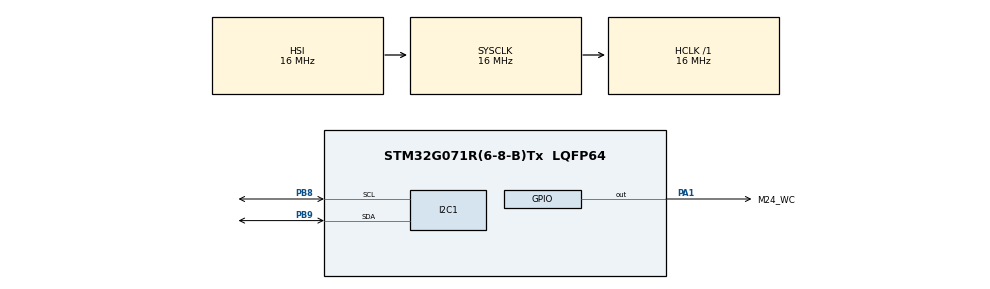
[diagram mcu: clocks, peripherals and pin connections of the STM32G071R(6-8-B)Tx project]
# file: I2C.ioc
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I2C1.Timing=0x00503D58
Mcu.Family=STM32G0
Mcu.Name=STM32G071R(6-8-B)Tx
Mcu.Package=LQFP64
PA1.GPIO_Label=M24_WC
PA1.Signal=GPIO_Output
PA13.Mode=Serial_Wire
PA13.Signal=SYS_SWDIO
PA14-BOOT0.Mode=Serial_Wire
PA14-BOOT0.Signal=SYS_SWCLK
PB8.Mode=I2C
PB8.Signal=I2C1_SCL
PB9.Mode=I2C
PB9.Signal=I2C1_SDA
ProjectManager.HeapSize=0x200
ProjectManager.StackSize=0x400
ProjectManager.TargetToolchain=STM32CubeIDE
RCC.AHBFreq_Value=16000000
RCC.CortexFreq_Value=16000000
RCC.EXTERNAL_CLOCK_VALUE=48000
RCC.HCLKFreq_Value=16000000
RCC.HSE_VALUE=8000000
RCC.HSI_VALUE=16000000
RCC.LSE_VALUE=32768
RCC.SYSCLKFreq_VALUE=16000000
RCC.VCOOutputFreq_Value=128000000
board=custom

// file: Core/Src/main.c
/* USER CODE BEGIN Header */
/**
  ******************************************************************************
  * @file           : main.c
  * @brief          : Main program body
  ******************************************************************************
  * @attention
  *
  * Copyright (c) 2024 STMicroelectronics.
  * All rights reserved.
  *
  * This software is licensed under terms that can be found in the LICENSE file
  * in the root directory of this software component.
  * If no LICENSE file comes with this software, it is provided AS-IS.
  *
  ******************************************************************************
  */
/* USER CODE END Header */
#include "main.h"
#include "i2c.h"
#include "gpio.h"
#include "M24.h"

void SystemClock_Config(void);

int main(void)
{

  /* USER CODE BEGIN 1 */

	uint8_t ReadValue =0;
	uint8_t M24Type;
	uint8_t TxData1 ='A';
	uint8_t TxData2 ='B';
	uint8_t TxData3 ='C';

  /* USER CODE END 1 */

  /* MCU Configuration--------------------------------------------------------*/

  /* Reset of all peripherals, Initializes the Flash interface and the Systick. */
  HAL_Init();

  /* Configure the system clock */
  SystemClock_Config();

  /* Initialize all configured peripherals */
  MX_GPIO_Init();
  MX_I2C1_Init();
  /* USER CODE BEGIN 2 */
  HAL_GPIO_WritePin(M24_WC_GPIO_Port,M24_WC_Pin, GPIO_PIN_RESET);

  /* USER CODE END 2 */

  /* Infinite loop */
  /* USER CODE BEGIN WHILE */
  while (1)
  {

	  M24Type =M24C02_I2C_ADDR;
	  WriteByteM24(M24Type,0x00000001,TxData1);
	  ReadValue =0;
	  ReadValue = ReadByteM24(M24Type,0x00000001);
	  if(TxData1 ==ReadValue) {
		  HAL_Delay(1);
	  }
	  M24Type =M24256_I2C_ADDR;
	  WriteByteM24(M24Type, 0x00000001,TxData2);
	  ReadValue =0;
	  ReadValue = ReadByteM24(M24Type,0x00000001);
	  if(TxData2 ==ReadValue) {
		  HAL_Delay(1);
	  }
	  M24Type =M24M01_I2C_ADDR;
	  WriteByteM24(M24Type, 0x00000001,TxData3);
	  ReadValue =0;
	  ReadValue = ReadByteM24(M24Type,0x00000001);
	  if(TxData3 ==ReadValue) {
		  HAL_Delay(1);
	  }

    /* USER CODE END WHILE */

  }
}

void SystemClock_Config(void)
{
  RCC_OscInitTypeDef RCC_OscInitStruct = {0};
  RCC_ClkInitTypeDef RCC_ClkInitStruct = {0};

  /** Configure the main internal regulator output voltage
  */
  HAL_PWREx_ControlVoltageScaling(PWR_REGULATOR_VOLTAGE_SCALE1);

  /** Initializes the RCC Oscillators according to the specified parameters
  * in the RCC_OscInitTypeDef structure.
  */
  RCC_OscInitStruct.OscillatorType = RCC_OSCILLATORTYPE_HSI;
  RCC_OscInitStruct.HSIState = RCC_HSI_ON;
  RCC_OscInitStruct.HSIDiv = RCC_HSI_DIV1;
  RCC_OscInitStruct.HSICalibrationValue = RCC_HSICALIBRATION_DEFAULT;
  RCC_OscInitStruct.PLL.PLLState = RCC_PLL_NONE;
  if (HAL_RCC_OscConfig(&RCC_OscInitStruct) != HAL_OK)
  {
    Error_Handler();
  }

  /** Initializes the CPU, AHB and APB buses clocks
  */
  RCC_ClkInitStruct.ClockType = RCC_CLOCKTYPE_HCLK|RCC_CLOCKTYPE_SYSCLK
                              |RCC_CLOCKTYPE_PCLK1;
  RCC_ClkInitStruct.SYSCLKSource = RCC_SYSCLKSOURCE_HSI;
  RCC_ClkInitStruct.AHBCLKDivider = RCC_SYSCLK_DIV1;
  RCC_ClkInitStruct.APB1CLKDivider = RCC_HCLK_DIV1;

  if (HAL_RCC_ClockConfig(&RCC_ClkInitStruct, FLASH_LATENCY_0) != HAL_OK)
  {
    Error_Handler();
  }
}

void Error_Handler(void)
{
  __disable_irq();
  while (1)
  {
  }
}
